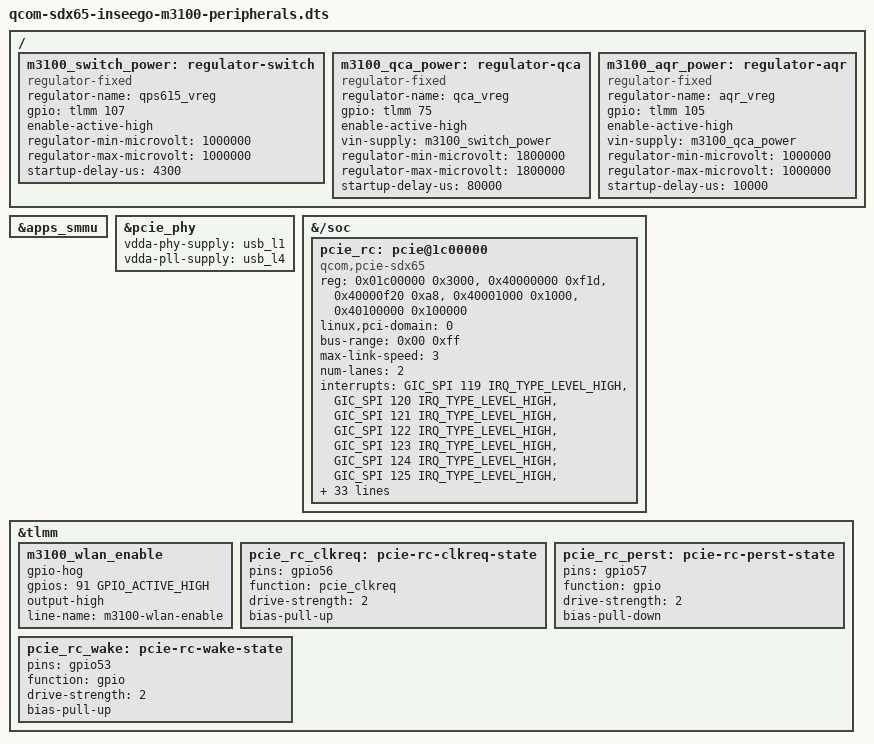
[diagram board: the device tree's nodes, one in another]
// SPDX-License-Identifier: BSD-3-Clause
/* M3100 PCIe RAM trial. Root-complex registers/driver follow SDX65 reference; reset GPIO57 and full SID topology match M3100 stock. No NAND or modem. */
#include "qcom-sdx65-inseego-m3100-ram.dts"
#include <dt-bindings/gpio/gpio.h>
#include <dt-bindings/regulator/qcom,rpmh-regulator.h>
#include "m3100-peripheral-extras.dtsi"
#include "m3100-pstore.dtsi"

/ {
	/* Exact stock enable GPIOs and voltage descriptions. The common rail
	 * powers the TC956x switch; do not use the H5 board's GPIO102.
	 */
	m3100_switch_power: regulator-switch {
		compatible = "regulator-fixed";
		regulator-name = "qps615_vreg";
		gpio = <&tlmm 107 GPIO_ACTIVE_HIGH>;
		enable-active-high;
		regulator-min-microvolt = <1000000>;
		regulator-max-microvolt = <1000000>;
		startup-delay-us = <4300>;
	};
	m3100_qca_power: regulator-qca {
		compatible = "regulator-fixed";
		regulator-name = "qca_vreg";
		gpio = <&tlmm 75 GPIO_ACTIVE_HIGH>;
		enable-active-high;
		vin-supply = <&m3100_switch_power>;
		regulator-min-microvolt = <1800000>;
		regulator-max-microvolt = <1800000>;
		startup-delay-us = <80000>;
	};
	m3100_aqr_power: regulator-aqr {
		compatible = "regulator-fixed";
		regulator-name = "aqr_vreg";
		gpio = <&tlmm 105 GPIO_ACTIVE_HIGH>;
		enable-active-high;
		vin-supply = <&m3100_qca_power>;
		regulator-min-microvolt = <1000000>;
		regulator-max-microvolt = <1000000>;
		startup-delay-us = <10000>;
	};
};

&apps_smmu {
	status = "okay";
};

&pcie_phy {
	vdda-phy-supply = <&usb_l1>;
	vdda-pll-supply = <&usb_l4>;
	status = "okay";
};

&{/soc} {
	pcie_rc: pcie@1c00000 {
		compatible = "qcom,pcie-sdx65";
		reg = <0x01c00000 0x3000>,
		      <0x40000000 0xf1d>,
		      <0x40000f20 0xa8>,
		      <0x40001000 0x1000>,
		      <0x40100000 0x100000>;
		reg-names = "parf", "dbi", "elbi", "atu", "config";
		device_type = "pci";
		linux,pci-domain = <0>;
		bus-range = <0x00 0xff>;
		max-link-speed = <3>;
		/* Stock root and switch upstream both negotiate x2 at 8 GT/s. */
		num-lanes = <2>;
		#address-cells = <3>;
		#size-cells = <2>;
		ranges = <0x01000000 0x0 0x00000000 0x40200000 0x0 0x100000>,
			 <0x02000000 0x0 0x40300000 0x40300000 0x0 0x3fd00000>;

		interrupts = <GIC_SPI 119 IRQ_TYPE_LEVEL_HIGH>,
			     <GIC_SPI 120 IRQ_TYPE_LEVEL_HIGH>,
			     <GIC_SPI 121 IRQ_TYPE_LEVEL_HIGH>,
			     <GIC_SPI 122 IRQ_TYPE_LEVEL_HIGH>,
			     <GIC_SPI 123 IRQ_TYPE_LEVEL_HIGH>,
			     <GIC_SPI 124 IRQ_TYPE_LEVEL_HIGH>,
			     <GIC_SPI 125 IRQ_TYPE_LEVEL_HIGH>,
			     <GIC_SPI 126 IRQ_TYPE_LEVEL_HIGH>;
		interrupt-names = "msi", "msi2", "msi3", "msi4",
				  "msi5", "msi6", "msi7", "msi8";
		#interrupt-cells = <1>;
		interrupt-map-mask = <0 0 0 0x7>;
		interrupt-map = <0 0 0 1 &intc 0 141 IRQ_TYPE_LEVEL_HIGH>,
				<0 0 0 2 &intc 0 142 IRQ_TYPE_LEVEL_HIGH>,
				<0 0 0 3 &intc 0 143 IRQ_TYPE_LEVEL_HIGH>,
				<0 0 0 4 &intc 0 144 IRQ_TYPE_LEVEL_HIGH>;

		clocks = <&gcc GCC_PCIE_PIPE_CLK>,
			 <&gcc GCC_PCIE_AUX_CLK>,
			 <&gcc GCC_PCIE_CFG_AHB_CLK>,
			 <&gcc GCC_PCIE_MSTR_AXI_CLK>,
			 <&gcc GCC_PCIE_SLV_AXI_CLK>,
			 <&gcc GCC_PCIE_SLV_Q2A_AXI_CLK>,
			 <&gcc GCC_PCIE_SLEEP_CLK>;
		clock-names = "pipe", "aux", "cfg", "bus_master",
			      "bus_slave", "slave_q2a", "sleep";
		resets = <&gcc GCC_PCIE_BCR>;
		reset-names = "pci";
		power-domains = <&gcc PCIE_GDSC>;
		phys = <&pcie_phy>;
		phy-names = "pciephy";
		vdda-supply = <&usb_l1>;
		vddpe-3v3-supply = <&m3100_aqr_power>;
		interconnects = <&system_noc MASTER_PCIE_0 &mc_virt SLAVE_EBI1>,
			       <&mem_noc MASTER_APPSS_PROC &system_noc SLAVE_PCIE_0>;
		interconnect-names = "pcie-mem", "cpu-pcie";
		iommu-map = <0x000 &apps_smmu 0x200 1>, <0x100 &apps_smmu 0x201 1>, <0x208 &apps_smmu 0x202 1>, <0x210 &apps_smmu 0x203 1>, <0x218 &apps_smmu 0x204 1>, <0x300 &apps_smmu 0x207 1>, <0x400 &apps_smmu 0x208 1>, <0x401 &apps_smmu 0x20a 1>, <0x500 &apps_smmu 0x20c 1>, <0x501 &apps_smmu 0x20e 1>;
		perst-gpios = <&tlmm 57 GPIO_ACTIVE_LOW>;
		pinctrl-0 = <&pcie_rc_clkreq &pcie_rc_perst &pcie_rc_wake>;
		pinctrl-names = "default";
		status = "okay";
	};
};

&tlmm {
	m3100_wlan_enable {
		gpio-hog;
		gpios = <91 GPIO_ACTIVE_HIGH>;
		output-high;
		line-name = "m3100-wlan-enable";
	};

	pcie_rc_clkreq: pcie-rc-clkreq-state {
		pins = "gpio56";
		function = "pcie_clkreq";
		drive-strength = <2>;
		bias-pull-up;
	};

	pcie_rc_perst: pcie-rc-perst-state {
		pins = "gpio57";
		function = "gpio";
		drive-strength = <2>;
		bias-pull-down;
	};

	pcie_rc_wake: pcie-rc-wake-state {
		pins = "gpio53";
		function = "gpio";
		drive-strength = <2>;
		bias-pull-up;
	};
};

#include "m3100-ethernet-resources.dtsi"

